# HDSC_HC32L176 register map
Vendor: HDSC Co.Ltd; Series: ARMCM0P; File version: 1.2
CPU: CM0 r0p0, little endian, no MPU, no FPU, 3 interrupt priority bits
Registers are 32-bit, read-write, reset 0x0 unless marked. A register's access mark holds for its fields unless they carry their own. Offsets are from the block's base; [hi:lo] are bit positions; {n}, {i} and the like mark numbered series.

## LVD
Base 0x40002400; alternate view of ADC
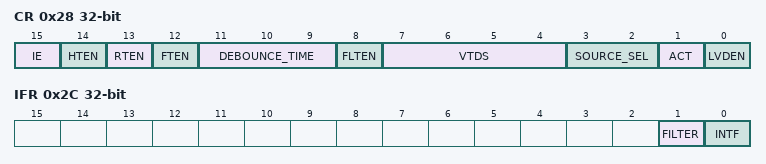
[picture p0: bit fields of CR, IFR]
0x28 CR
  [15] IE, [14] HTEN, [13] RTEN, [12] FTEN, [11:9] DEBOUNCE_TIME, [8] FLTEN, [7:4] VTDS, [3:2] SOURCE_SEL, [1] ACT, [0] LVDEN
0x2C IFR
  [1] FILTER, [0] INTF

## OPA
Base 0x40002400; alternate view of ADC
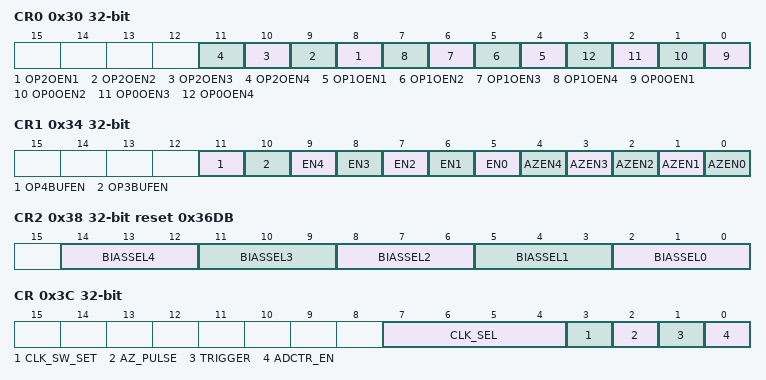
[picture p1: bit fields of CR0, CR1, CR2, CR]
0x30 CR0
  [n+7] OP2OEN{n} (n=1..4), [n+3] OP1OEN{n} (n=1..4), [n-1] OP0OEN{n} (n=1..4)
0x34 CR1
  [11] OP4BUFEN, [10] OP3BUFEN, [n+5] EN{n} (n=0..4), [n] AZEN{n} (n=0..4)
0x38 CR2 reset 0x36DB
  [3n+2:3n] BIASSEL{n} (n=0..4)
0x3C CR
  [7:4] CLK_SEL, [3] CLK_SW_SET, [2] AZ_PULSE, [1] TRIGGER, [0] ADCTR_EN

## PCA
Base 0x40001000
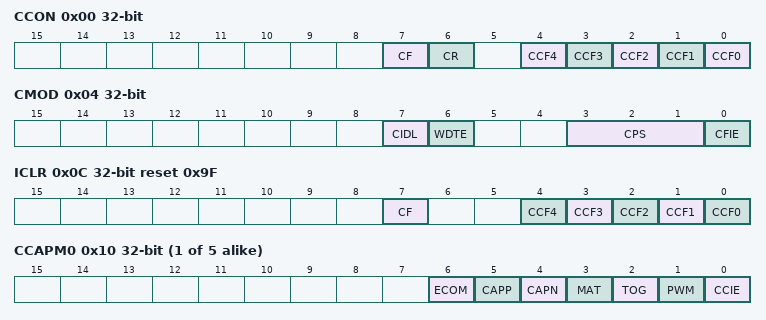
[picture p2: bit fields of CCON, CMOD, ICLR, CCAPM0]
0x00 CCON
  [7] CF, [6] CR, [n] CCF{n} (n=0..4)
0x04 CMOD
  [7] CIDL, [6] WDTE, [3:1] CPS, [0] CFIE
0x08 CNT
  [15:0] CNT
0x0C ICLR wo reset 0x9F
  [7] CF, [n] CCF{n} (n=0..4)
{0x10+4i} CCAPM{i} (i=0..4)
  [6] ECOM, [5] CAPP, [4] CAPN, [3] MAT, [2] TOG, [1] PWM, [0] CCIE
{0x24+8i} CCAP{i}H (i=0..4)
  [7:0] CCAP{i}
{0x28+8i} CCAP{i}L (i=0..4)
  [7:0] CCAP{i}
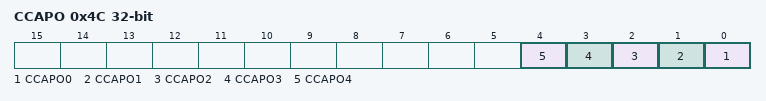
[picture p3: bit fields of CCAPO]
0x4C CCAPO
  [n] CCAPO{n} (n=0..4)
{0x50+4i} CCAP{i} (i=0..4)
  [15:0] CCAP{i}
0x64 CARR
  [15:0] CARR
0x68 EPWM
  [0] EPWM

## PCNT
Base 0x40005400
0x00 RUN 8-bit
  [0] RUN
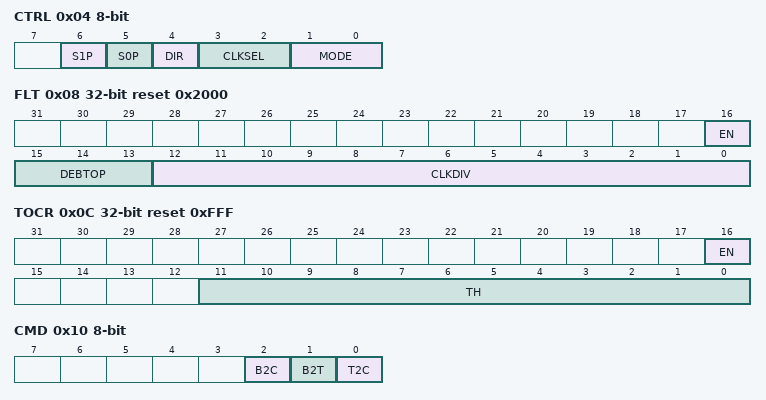
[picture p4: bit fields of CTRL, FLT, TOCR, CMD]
0x04 CTRL 8-bit
  [6] S1P, [5] S0P, [4] DIR, [3:2] CLKSEL, [1:0] MODE
0x08 FLT reset 0x2000
  [16] EN, [15:13] DEBTOP, [12:0] CLKDIV
0x0C TOCR reset 0xFFF
  [16] EN, [11:0] TH
0x10 CMD 8-bit wo
  [2] B2C, [1] B2T, [0] T2C
0x14 SR1 8-bit ro
  [0] DIR
0x18 CNT 16-bit ro
0x1C TOP 16-bit ro reset 0xFF
0x20 BUF 16-bit reset 0xFF
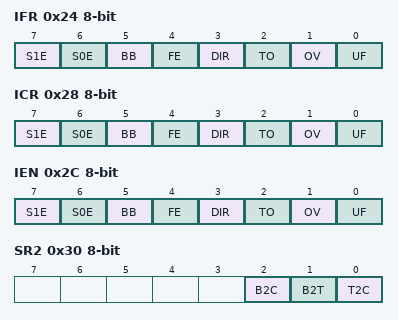
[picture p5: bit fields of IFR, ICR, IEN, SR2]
0x24 IFR 8-bit ro
  [7] S1E, [6] S0E, [5] BB, [4] FE, [3] DIR, [2] TO, [1] OV, [0] UF
0x28 ICR 8-bit wo
  [7] S1E, [6] S0E, [5] BB, [4] FE, [3] DIR, [2] TO, [1] OV, [0] UF
0x2C IEN 8-bit
  [7] S1E, [6] S0E, [5] BB, [4] FE, [3] DIR, [2] TO, [1] OV, [0] UF
0x30 SR2 8-bit ro
  [2] B2C, [1] B2T, [0] T2C

## RAM
Base 0x40020400
0x00 CR
  [1] IE
0x04 ERRADDR ro (reset mask 0x1FFF)
  [13:0] ERRADDR
0x08 IFR ro
  [0] ERR
0x0C ICLR wo reset 0x1
  [0] ERRCLR

## RESET
Base 0x4000201C
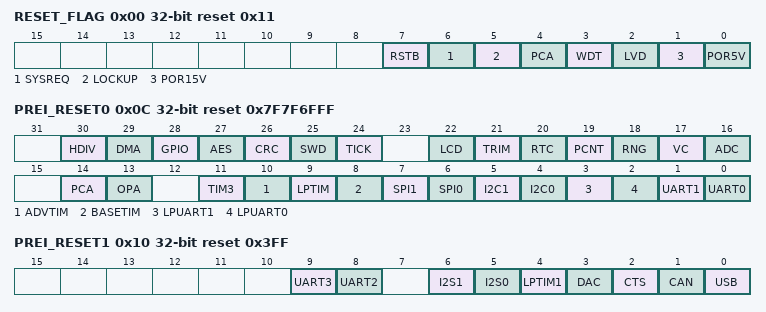
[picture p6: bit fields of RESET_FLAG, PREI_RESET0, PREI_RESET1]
0x00 RESET_FLAG reset 0x11
  [7] RSTB, [6] SYSREQ, [5] LOCKUP, [4] PCA, [3] WDT, [2] LVD, [1] POR15V, [0] POR5V
0x0C PREI_RESET0 reset 0x7F7F6FFF
  [30] HDIV, [29] DMA, [28] GPIO, [27] AES, [26] CRC, [25] SWD, [24] TICK, [22] LCD, [21] TRIM, [20] RTC, [19] PCNT, [18] RNG, [17] VC, [16] ADC, [14] PCA, [13] OPA, [11] TIM3, [10] ADVTIM, [9] LPTIM, [8] BASETIM, [7] SPI1, [6] SPI0, [5] I2C1, [4] I2C0, [3] LPUART1, [2] LPUART0, [1] UART1, [0] UART0
0x10 PREI_RESET1 reset 0x3FF
  [9] UART3, [8] UART2, [6] I2S1, [5] I2S0, [4] LPTIM1, [3] DAC, [2] CTS, [1] CAN, [0] USB

## RTC
Base 0x40001400
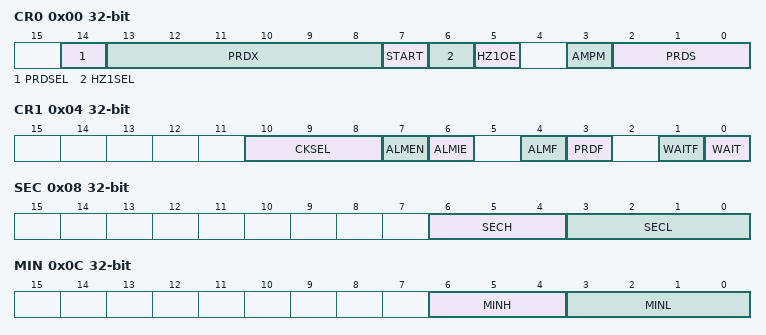
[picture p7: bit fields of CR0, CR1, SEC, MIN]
0x00 CR0
  [14] PRDSEL, [13:8] PRDX, [7] START, [6] HZ1SEL, [5] HZ1OE, [3] AMPM, [2:0] PRDS
0x04 CR1
  [10:8] CKSEL, [7] ALMEN, [6] ALMIE, [4] ALMF, [3] PRDF, [1] WAITF, [0] WAIT
0x08 SEC
  [6:4] SECH, [3:0] SECL
0x0C MIN
  [6:4] MINH, [3:0] MINL
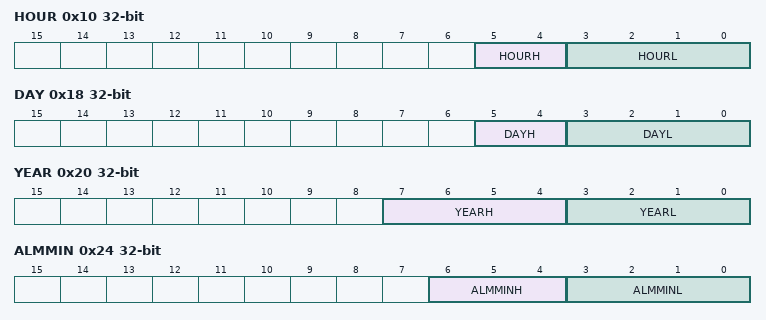
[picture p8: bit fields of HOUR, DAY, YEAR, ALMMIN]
0x10 HOUR
  [5:4] HOURH, [3:0] HOURL
0x14 WEEK
  [2:0] WEEK
0x18 DAY
  [5:4] DAYH, [3:0] DAYL
0x1C MON
  [4:0] MON
0x20 YEAR
  [7:4] YEARH, [3:0] YEARL
0x24 ALMMIN
  [6:4] ALMMINH, [3:0] ALMMINL
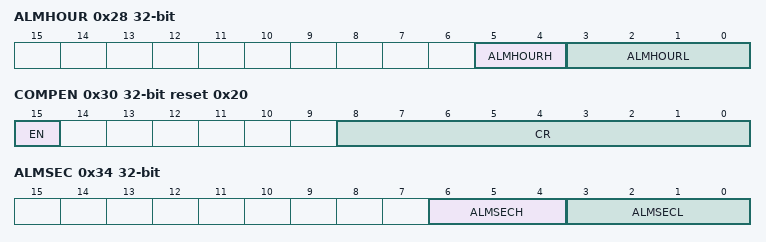
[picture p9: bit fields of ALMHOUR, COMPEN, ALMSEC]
0x28 ALMHOUR
  [5:4] ALMHOURH, [3:0] ALMHOURL
0x2C ALMWEEK
  [6:0] ALMWEEK
0x30 COMPEN reset 0x20
  [15] EN, [8:0] CR
0x34 ALMSEC
  [6:4] ALMSECH, [3:0] ALMSECL

## SPI0 — desc SPI
Base 0x40000800
Same registers: SPI1 0x40004800
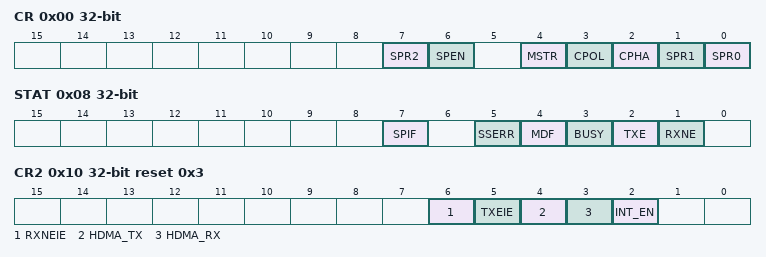
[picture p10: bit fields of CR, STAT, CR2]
0x00 CR
  [7] SPR2, [6] SPEN, [4] MSTR, [3] CPOL, [2] CPHA, [1] SPR1, [0] SPR0
0x04 SSN reset 0x1
  [0] SSN
0x08 STAT ro
  [7] SPIF, [5] SSERR, [4] MDF, [3] BUSY, [2] TXE, [1] RXNE
0x0C DATA
  [7:0] DAT
0x10 CR2 reset 0x3
  [6] RXNEIE, [5] TXEIE, [4] HDMA_TX, [3] HDMA_RX, [2] INT_EN
0x14 ICLR wo reset 0xFFFFFFFF
  [0] INT_CLR
